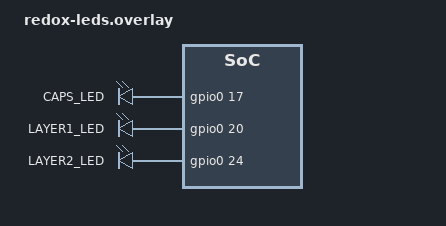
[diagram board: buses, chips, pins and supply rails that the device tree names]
/ {
    leds {
        compatible = "gpio-leds";

        caps_led: caps_led {
            gpios = <&gpio0 17 GPIO_ACTIVE_HIGH>;
            label = "CAPS_LED";
        };

        layer1_led: layer1_led {
            gpios = <&gpio0 20 GPIO_ACTIVE_HIGH>;
            label = "LAYER1_LED";
        };

        layer2_led: layer2_led {
            gpios = <&gpio0 24 GPIO_ACTIVE_HIGH>;
            label = "LAYER2_LED";
        };
    };
};
